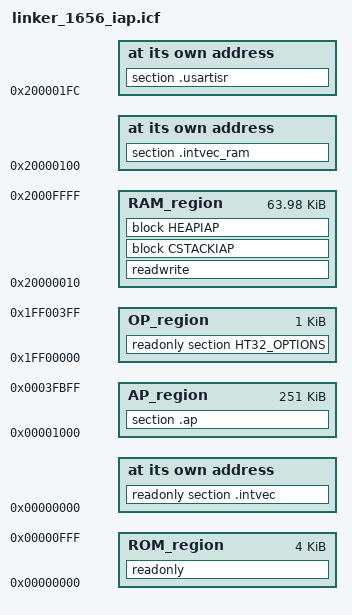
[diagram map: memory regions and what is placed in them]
/*###ICF### Section handled by ICF editor, don't touch! ****/
/*-Editor annotation file-*/
/* IcfEditorFile="$TOOLKIT_DIR$\config\ide\IcfEditor\cortex_v1_0.xml" */
/*-Specials-*/
define symbol __ICFEDIT_intvec_start__ = 0x00000000;
/*-Memory Regions-*/
define symbol __ICFEDIT_region_ROM_start__ = 0x00000000;
define symbol __ICFEDIT_region_ROM_end__   = 0x0003FBFF;
define symbol __ICFEDIT_region_RAM_start__ = 0x20000010;
define symbol __ICFEDIT_region_RAM_end__   = 0x2000FFFF;
/*-Sizes-*/
define symbol __ICFEDIT_size_cstack__ = 0x200;
define symbol __ICFEDIT_size_heap__   = 0x0;
/**** End of ICF editor section. ###ICF###*/

define symbol usart_vector_start     = 0x200001FC;  //IAP UART SETTING: Vector address of USART0
//define symbol usart_vector_start     = 0x20000200;  //IAP UART SETTING: Vector address of USART1

define symbol ram_intvec_start__     = 0x20000100;

define symbol iap_rom_end            = 0xFFF;
define symbol ap_rom_start           = iap_rom_end + 1;

define memory mem with size = 4G;
define region ROM_region   = mem:[from __ICFEDIT_region_ROM_start__ to iap_rom_end];
define region RAM_region   = mem:[from __ICFEDIT_region_RAM_start__ to __ICFEDIT_region_RAM_end__];
define region AP_region    = mem:[from ap_rom_start                 to __ICFEDIT_region_ROM_end__];

define block CSTACKIAP    with alignment = 8, size = __ICFEDIT_size_cstack__   { };
define block HEAPIAP      with alignment = 8, size = __ICFEDIT_size_heap__     { };

initialize by copy { readonly, readwrite }
            except { section .intvec,
                     section .resetinit,
                     section .ap,
                   };

do not initialize  { section .noinit };

place at address mem:__ICFEDIT_intvec_start__ { readonly section .intvec };
place at address mem:usart_vector_start       { section .usartisr };
place at address mem:ram_intvec_start__       { section .intvec_ram };

place in ROM_region   { readonly };
place in RAM_region   { readwrite, block CSTACKIAP, block HEAPIAP };
place in AP_region    { section .ap };

define symbol op_rom_start       = 0x1FF00000;
define symbol op_rom_end         = 0x1FF003FF;
define region OP_region    = mem:[from op_rom_start to op_rom_end];
place in OP_region    { readonly section HT32_OPTIONS };
